# PER_AP register map
Vendor: Texas Instruments
Peripheral module from a debugger description file (folder omap4460).
Registers are 32-bit, read-only, reset 0x0 unless marked. A register's access mark holds for its fields unless they carry their own. Offsets are as the file gives them; lines under a group give offsets from that group; [hi:lo] are bit positions; {n}, {i} and the like mark numbered series; 'fields as' and 'values as' point back to an identical list; <NAME> marks a mode.

## PER_AP
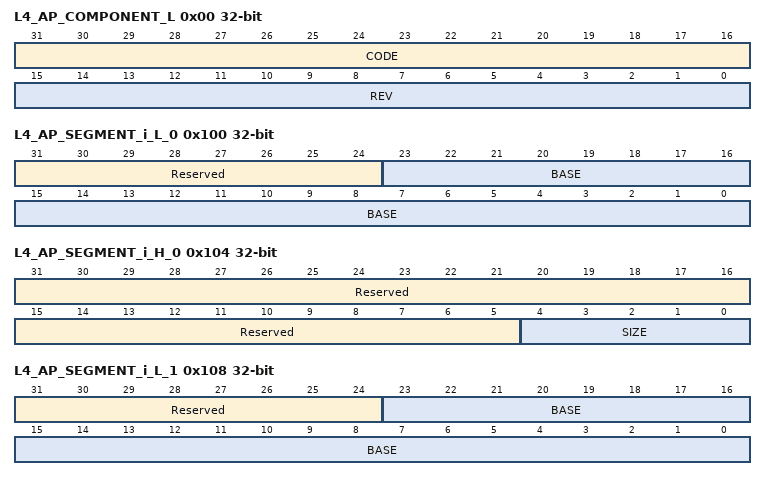
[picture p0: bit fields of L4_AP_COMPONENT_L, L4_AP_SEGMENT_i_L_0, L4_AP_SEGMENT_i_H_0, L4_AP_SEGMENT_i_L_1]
0x00 L4_AP_COMPONENT_L reset not defined — Contains a component code and revision, which are used to identify the hardware of the component.
  [31:16] CODE — Interconnect code
  [15:0] REV — Component revision code
0x04 L4_AP_COMPONENT_H — Contains a component code and revision, which are used to identify the hardware of the component.
  [31:0] Reserved — Read returns 0
0x100 L4_AP_SEGMENT_i_L_0 (reset mask 0xFF000000) — Define the base address of each segments
  [31:24] Reserved — Read returns 0.
  [23:0] BASE — The base address of the segment (with 0s from bit 0 to bit SIZE-1).
0x104 L4_AP_SEGMENT_i_H_0 (reset mask 0xFFFFFFE0) — Define the size of each segments
  [31:5] Reserved — Read returns 0.
  [4:0] SIZE — Segment size is a power of 2, where 2 is the byte size of a segment (all segment registers use the same size).
0x108 L4_AP_SEGMENT_i_L_1 (reset mask 0xFF000000) — Define the base address of each segments
  fields as L4_AP_SEGMENT_i_L_0
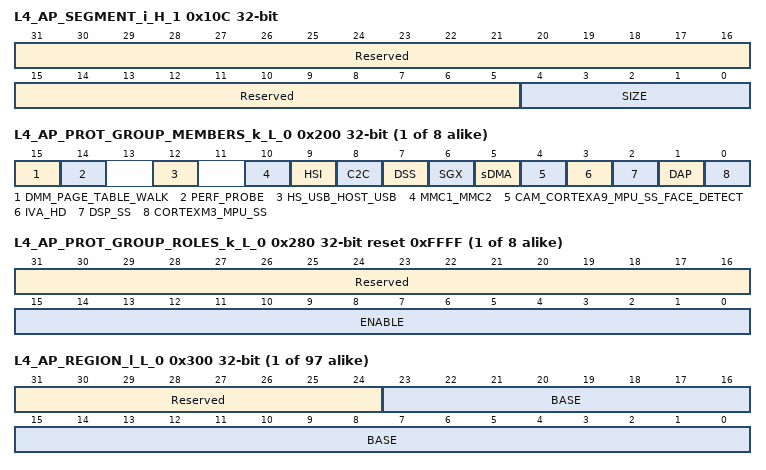
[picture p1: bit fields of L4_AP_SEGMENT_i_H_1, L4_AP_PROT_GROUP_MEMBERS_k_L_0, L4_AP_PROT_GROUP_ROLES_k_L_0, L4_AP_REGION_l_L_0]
0x10C L4_AP_SEGMENT_i_H_1 (reset mask 0xFFFFFFE0) — Define the size of each segments
  fields as L4_AP_SEGMENT_i_H_0
{0x200+8i} L4_AP_PROT_GROUP_MEMBERS_k_L_{i} access per field (reset mask 0xFFFF0000) (i=0..7) — Define ConnID bit vectors for a protection group.
  [15] DMM_PAGE_TABLE_WALK rw — Included in the protection group k0x0: Not a member0x1: Member
  [14] PERF_PROBE rw — Included in the protection group k0x0: Not a member0x1: Member
  [12] HS_USB_HOST_USB rw — Included in the protection group k0x0: Not a member0x1: Member
  [10] MMC1_MMC2 rw — Included in the protection group k0x0: Not a member0x1: Member
  [9] HSI rw — Included in the protection group k0x0: Not a member0x1: Member
  [8] C2C rw — Included in the protection group k0x0: Not a member0x1: Member
  [7] DSS rw — Included in the protection group k0x0: Not a member0x1: Member
  [6] SGX rw — Included in the protection group k0x0: Not a member0x1: Member
  [5] sDMA rw — Included in the protection group k0x0: Not a member0x1: Member
  [4] CAM_CORTEXA9_MPU_SS_FACE_DETECT rw — Included in the protection group k0x0: Not a member0x1: Member
  [3] IVA_HD rw — Included in the protection group k0x0: Not a member0x1: Member
  [2] DSP_SS rw — Included in the protection group k0x0: Not a member0x1: Member
  [1] DAP rw — Included in the protection group k0x0: Not a member0x1: Member
  [0] CORTEXM3_MPU_SS rw — Included in the protection group k0x0: Not a member0x1: Member
{0x204+8i} L4_AP_PROT_GROUP_MEMBERS_k_H_{i} (i=0..7) — Define ConnID bit vectors for a protection group.
  [31:0] Reserved — Read returns 0's
{0x280+8i} L4_AP_PROT_GROUP_ROLES_k_L_{i} reset 0xFFFF (i=0..7) — Define MReqInfo bit vectors for a protection group.
  [31:16] Reserved — Read returns 0
  [15:0] ENABLE — Setting of type acces allowed for the group of initiators.
{0x284+8i} L4_AP_PROT_GROUP_ROLES_k_H_{i} (i=0..7) — Define ConnID bit vectors for a protection group.
  [31:0] Reserved — Read returns 0's
{0x300+8i} L4_AP_REGION_l_L_{i} (reset mask 0xFF000000) (i=0..96) — Define the base address of the region in respect to the segment it belongs to.
  [31:24] Reserved — Read returns 0.
  [23:0] BASE — Sets the base address of the region relative to its segment base.
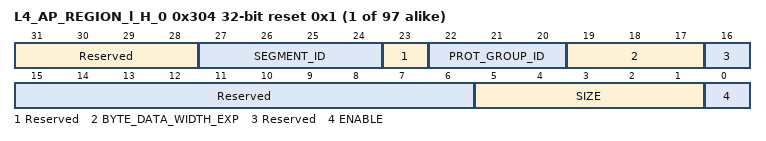
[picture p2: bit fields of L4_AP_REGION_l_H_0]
{0x304+8i} L4_AP_REGION_l_H_{i} access per field reset 0x1 (reset mask 0xF081FFC1) (i=0..96) — Define the size, protection group and segment ID of the region
  [31:28] Reserved ro — Read returns 0
  [27:24] SEGMENT_ID ro — The segment associated to the region.
  [23] Reserved ro — Read returns 0.
  [22:20] PROT_GROUP_ID rw — The protection group associated to the region.
  [19:17] BYTE_DATA_WIDTH_EXP ro — The target data byte width is 2 bytes.
  [16:6] Reserved ro — Read returns 0.
  [5:1] SIZE ro — Define the size of the region in bytes. 2 equals the region.
  [0] ENABLE ro — 0x0: Disable the region, no access allows0x1: Enable the region, with access as define in registers
